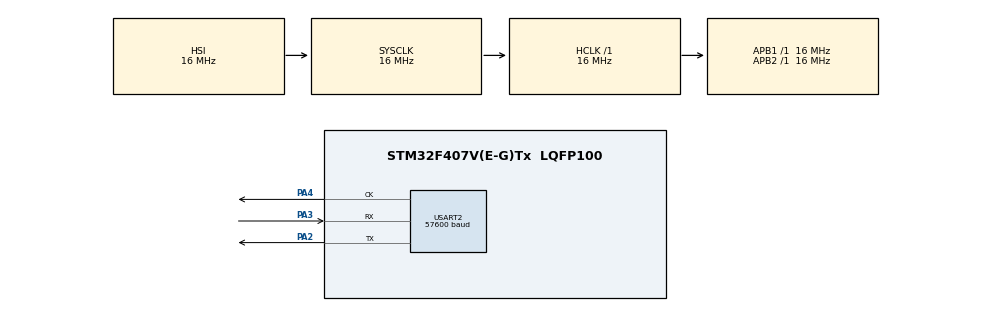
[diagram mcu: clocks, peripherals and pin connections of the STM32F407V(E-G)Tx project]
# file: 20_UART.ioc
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Mcu.Family=STM32F4
Mcu.Name=STM32F407V(E-G)Tx
Mcu.Package=LQFP100
NVIC.PriorityGroup=NVIC_PRIORITYGROUP_4
PA2.Mode=Synchronous
PA2.Signal=USART2_TX
PA3.Mode=Synchronous
PA3.Signal=USART2_RX
PA4.Mode=Synchronous
PA4.Signal=USART2_CK
ProjectManager.HeapSize=0x200
ProjectManager.StackSize=0x400
ProjectManager.TargetToolchain=STM32CubeIDE
RCC.AHBFreq_Value=16000000
RCC.APB1Freq_Value=16000000
RCC.APB2Freq_Value=16000000
RCC.CortexFreq_Value=16000000
RCC.HSE_VALUE=25000000
RCC.HSI_VALUE=16000000
RCC.LSE_VALUE=32768
RCC.SYSCLKFreq_VALUE=16000000
RCC.VCOOutputFreq_Value=192000000
USART2.BaudRate=57600
USART2.VirtualMode=VM_SYNC
board=custom

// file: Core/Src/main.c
/* USER CODE BEGIN Header */
/**
  ******************************************************************************
  * @file           : main.c
  * @brief          : Main program body
  ******************************************************************************
  * @attention
  *
  * Copyright (c) 2025 STMicroelectronics.
  * All rights reserved.
  *
  * This software is licensed under terms that can be found in the LICENSE file
  * in the root directory of this software component.
  * If no LICENSE file comes with this software, it is provided AS-IS.
  *
  ******************************************************************************
  */
/* USER CODE END Header */
#include "main.h"

/* USER CODE BEGIN Includes */
#include<string.h>
/* USER CODE END Includes */

USART_HandleTypeDef husart2;

/* USER CODE BEGIN PV */
char *firstMessage = "Hello World\r\n";
char recieveBuffer[10];
/* USER CODE END PV */

void SystemClock_Config(void);
static void MX_GPIO_Init(void);
static void MX_USART2_Init(void);

int main(void)
{

  /* MCU Configuration--------------------------------------------------------*/

  /* Reset of all peripherals, Initializes the Flash interface and the Systick. */
  HAL_Init();

  /* Configure the system clock */
  SystemClock_Config();

  /* Initialize all configured peripherals */
  MX_GPIO_Init();
  MX_USART2_Init();

  /* Infinite loop */
  while (1)
  {

    /* USER CODE BEGIN 3 */
	//  HAL_USART_Transmit(&husart2,(uint8_t*)firstMessage ,strlen(firstMessage), HAL_MAX_DELAY);
	//  HAL_Delay(1000);
	  HAL_USART_Receive(&husart2,recieveBuffer,5, HAL_MAX_DELAY);
  }
  /* USER CODE END 3 */
}

void SystemClock_Config(void)
{
  RCC_OscInitTypeDef RCC_OscInitStruct = {0};
  RCC_ClkInitTypeDef RCC_ClkInitStruct = {0};

  /** Configure the main internal regulator output voltage
  */
  __HAL_RCC_PWR_CLK_ENABLE();
  __HAL_PWR_VOLTAGESCALING_CONFIG(PWR_REGULATOR_VOLTAGE_SCALE1);

  /** Initializes the RCC Oscillators according to the specified parameters
  * in the RCC_OscInitTypeDef structure.
  */
  RCC_OscInitStruct.OscillatorType = RCC_OSCILLATORTYPE_HSI;
  RCC_OscInitStruct.HSIState = RCC_HSI_ON;
  RCC_OscInitStruct.HSICalibrationValue = RCC_HSICALIBRATION_DEFAULT;
  RCC_OscInitStruct.PLL.PLLState = RCC_PLL_NONE;
  if (HAL_RCC_OscConfig(&RCC_OscInitStruct) != HAL_OK)
  {
    Error_Handler();
  }

  /** Initializes the CPU, AHB and APB buses clocks
  */
  RCC_ClkInitStruct.ClockType = RCC_CLOCKTYPE_HCLK|RCC_CLOCKTYPE_SYSCLK
                              |RCC_CLOCKTYPE_PCLK1|RCC_CLOCKTYPE_PCLK2;
  RCC_ClkInitStruct.SYSCLKSource = RCC_SYSCLKSOURCE_HSI;
  RCC_ClkInitStruct.AHBCLKDivider = RCC_SYSCLK_DIV1;
  RCC_ClkInitStruct.APB1CLKDivider = RCC_HCLK_DIV1;
  RCC_ClkInitStruct.APB2CLKDivider = RCC_HCLK_DIV1;

  if (HAL_RCC_ClockConfig(&RCC_ClkInitStruct, FLASH_LATENCY_0) != HAL_OK)
  {
    Error_Handler();
  }
}

static void MX_USART2_Init(void)
{

  husart2.Instance = USART2;
  husart2.Init.BaudRate = 57600;
  husart2.Init.WordLength = USART_WORDLENGTH_8B;
  husart2.Init.StopBits = USART_STOPBITS_1;
  husart2.Init.Parity = USART_PARITY_NONE;
  husart2.Init.Mode = USART_MODE_TX_RX;
  husart2.Init.CLKPolarity = USART_POLARITY_LOW;
  husart2.Init.CLKPhase = USART_PHASE_1EDGE;
  husart2.Init.CLKLastBit = USART_LASTBIT_DISABLE;
  if (HAL_USART_Init(&husart2) != HAL_OK)
  {
    Error_Handler();
  }

}

static void MX_GPIO_Init(void)
{

  /* GPIO Ports Clock Enable */
  __HAL_RCC_GPIOA_CLK_ENABLE();

}

void Error_Handler(void)
{
  __disable_irq();
  while (1)
  {
  }
}
